VERSION "0.1.0"

NS_ :

BS_:

BU_: CENTRAL ENGINE BRAKES LIGHTING DASHBOARD

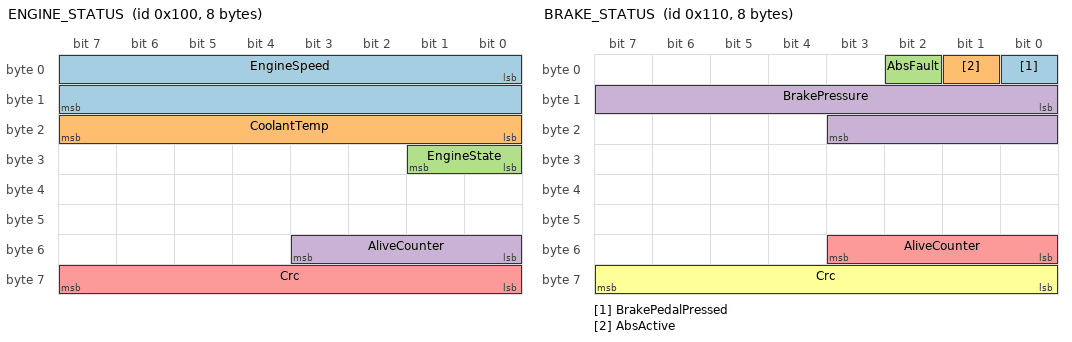
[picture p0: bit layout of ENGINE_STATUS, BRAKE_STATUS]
BO_ 256 ENGINE_STATUS: 8 ENGINE
 SG_ EngineSpeed : 0|16@1+ (0.25,0) [0|8000] "rpm" CENTRAL,DASHBOARD
 SG_ CoolantTemp : 16|8@1+ (1,-40) [-40|215] "degC" CENTRAL,DASHBOARD
 SG_ EngineState : 24|2@1+ (1,0) [0|2] "" CENTRAL,DASHBOARD
 SG_ AliveCounter : 48|4@1+ (1,0) [0|15] "" CENTRAL
 SG_ Crc : 56|8@1+ (1,0) [0|255] "" CENTRAL

BO_ 272 BRAKE_STATUS: 8 BRAKES
 SG_ BrakePedalPressed : 0|1@1+ (1,0) [0|1] "" CENTRAL,DASHBOARD
 SG_ AbsActive : 1|1@1+ (1,0) [0|1] "" CENTRAL,DASHBOARD
 SG_ AbsFault : 2|1@1+ (1,0) [0|1] "" CENTRAL,DASHBOARD
 SG_ BrakePressure : 8|12@1+ (0.1,0) [0|250] "bar" CENTRAL,DASHBOARD
 SG_ AliveCounter : 48|4@1+ (1,0) [0|15] "" CENTRAL
 SG_ Crc : 56|8@1+ (1,0) [0|255] "" CENTRAL

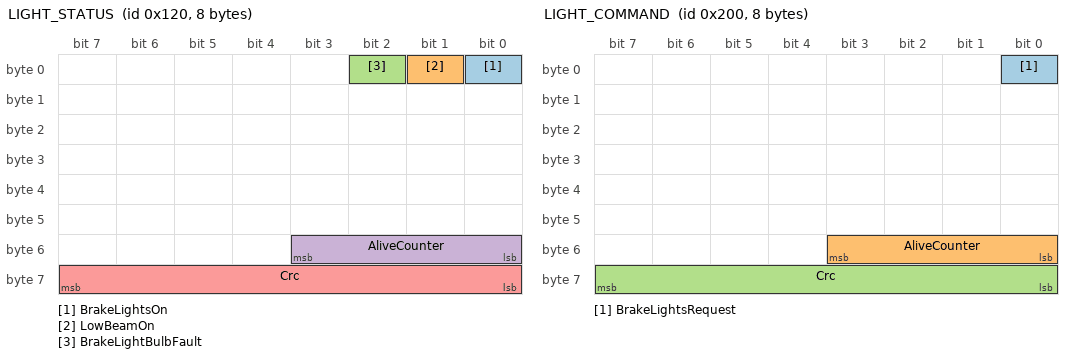
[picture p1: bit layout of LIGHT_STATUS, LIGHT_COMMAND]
BO_ 288 LIGHT_STATUS: 8 LIGHTING
 SG_ BrakeLightsOn : 0|1@1+ (1,0) [0|1] "" CENTRAL,DASHBOARD
 SG_ LowBeamOn : 1|1@1+ (1,0) [0|1] "" CENTRAL,DASHBOARD
 SG_ BrakeLightBulbFault : 2|1@1+ (1,0) [0|1] "" CENTRAL,DASHBOARD
 SG_ AliveCounter : 48|4@1+ (1,0) [0|15] "" CENTRAL
 SG_ Crc : 56|8@1+ (1,0) [0|255] "" CENTRAL

BO_ 512 LIGHT_COMMAND: 8 CENTRAL
 SG_ BrakeLightsRequest : 0|1@1+ (1,0) [0|1] "" LIGHTING
 SG_ AliveCounter : 48|4@1+ (1,0) [0|15] "" LIGHTING
 SG_ Crc : 56|8@1+ (1,0) [0|255] "" LIGHTING

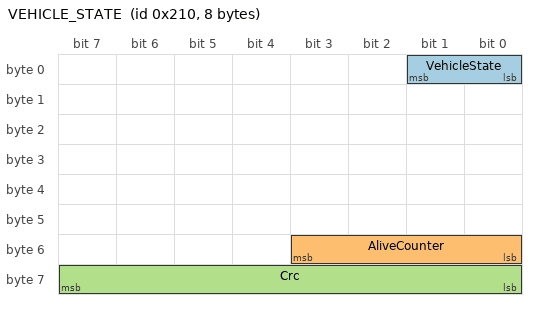
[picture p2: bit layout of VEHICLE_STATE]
BO_ 528 VEHICLE_STATE: 8 CENTRAL
 SG_ VehicleState : 0|2@1+ (1,0) [0|3] "" ENGINE,BRAKES,LIGHTING,DASHBOARD
 SG_ AliveCounter : 48|4@1+ (1,0) [0|15] "" ENGINE,BRAKES,LIGHTING,DASHBOARD
 SG_ Crc : 56|8@1+ (1,0) [0|255] "" ENGINE,BRAKES,LIGHTING,DASHBOARD

CM_ "Car central computer - communication matrix, phase 1 (engine, brakes, lighting).";
CM_ BU_ CENTRAL "Central computer (gateway).";
CM_ BU_ DASHBOARD "Dashboard unit: listens to all status messages.";
CM_ BO_ 256 "Engine status, sent every 20 ms.";
CM_ BO_ 272 "Brakes and ABS status, sent every 20 ms.";
CM_ BO_ 288 "Lighting status, sent every 20 ms.";
CM_ BO_ 512 "Lighting command from the central computer, sent every 20 ms.";
CM_ BO_ 528 "Vehicle state from the central computer, sent every 20 ms (SYS_STATE_001).";
CM_ SG_ 256 AliveCounter "E2E alive counter, +1 every send, wraps 15 to 0 (ADR 0007).";
CM_ SG_ 256 Crc "E2E CRC-8 SAE J1850 over the message ID and bytes 0-6 (ADR 0007).";
CM_ SG_ 272 BrakePedalPressed "Brake pedal state; drives the brake lights (SYS_LIGHT_001, SYS_LIGHT_002).";
CM_ SG_ 288 BrakeLightBulbFault "A brake light bulb is broken; a Warning-severity fault.";
CM_ SG_ 528 VehicleState "One vehicle state for the whole car (SYS_STATE_001).";
BA_DEF_  "BusType" STRING ;
BA_DEF_  "Baudrate" INT 0 1000000;
BA_DEF_ BO_  "GenMsgCycleTime" INT 0 65535;
BA_DEF_DEF_  "BusType" "CAN";
BA_DEF_DEF_  "Baudrate" 500000;
BA_DEF_DEF_  "GenMsgCycleTime" 0;
BA_ "GenMsgCycleTime" BO_ 256 20;
BA_ "GenMsgCycleTime" BO_ 272 20;
BA_ "GenMsgCycleTime" BO_ 288 20;
BA_ "GenMsgCycleTime" BO_ 512 20;
BA_ "GenMsgCycleTime" BO_ 528 20;
VAL_ 256 EngineState 0 "Off" 1 "Running" 2 "Fault" ;
VAL_ 528 VehicleState 0 "Starting" 1 "Normal" 2 "Limited" 3 "Safe" ;
